# AVR32SD28 device description
Architecture: AVR8X; Family: AVR
Registers are 8-bit, read-write, reset 0x0 unless marked. A register's access mark holds for its fields unless they carry their own. Offsets are from the block's base; [hi:lo] are bit positions; {n}, {i} and the like mark numbered series; <NAME> marks a mode.

## AC — Analog Comparator
Instances: AC0 0x0680, AC1 0x0688, AC2 0x0690
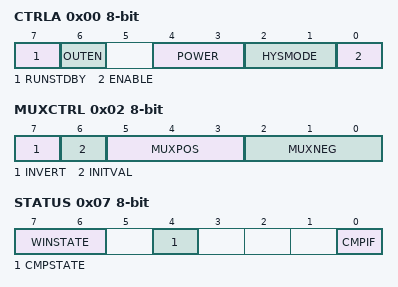
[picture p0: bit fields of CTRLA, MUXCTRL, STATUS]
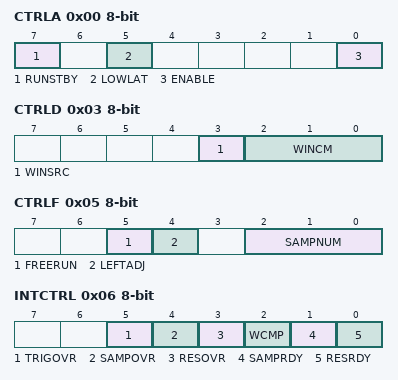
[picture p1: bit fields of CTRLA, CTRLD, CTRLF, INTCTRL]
0x00 CTRLA — Control A
  [7] RUNSTDBY — Run in Standby Mode
  [6] OUTEN — Output Pad Enable
  [4:3] POWER — Power profile
    0=PROFILE0 (Power profile 0, Shortest response time, highest consumption); 1=PROFILE1 (Power profile 1); 2=PROFILE2 (Power profile 2)
  [2:1] HYSMODE — Hysteresis Mode
    0=NONE (No hysteresis); 1=SMALL (Small hysteresis); 2=MEDIUM (Medium hysteresis); 3=LARGE (Large hysteresis)
  [0] ENABLE
0x01 CTRLB — Control B
  [1:0] WINSEL — Window selection mode
    0=DISABLED (Window function disabled); 1=UPSEL1 (Select ACn+1 as upper limit in window compare); 2=UPSEL2 (Select ACn+2 as upper limit in window compare)
0x02 MUXCTRL — Mux Control A
  [7] INVERT — Invert AC Output
  [6] INITVAL — AC Output Initial Value
    0=LOW (Output initialized to 0); 1=HIGH (Output initialized to 1)
  [5:3] MUXPOS — Positive Input MUX Selection
    {v}=AINP{v} (Positive Pin {v}) (v=0..4)
  [2:0] MUXNEG — Negative Input MUX Selection
    0=AINN0 (Negative Pin 0); 2=AINN2 (Negative Pin 2); 3=AINN3 (Negative Pin 3); 4=DACREF (DAC Reference)
0x05 DACREF reset 0xFF — DAC Voltage Reference
0x06 INTCTRL (modes: NORMAL when AC.CTRLB.WINSEL=0x0; WINDOW when AC.CTRLB.WINSEL=0x1 0x2) — Interrupt Control
  [0] CMP — Interrupt Enable
  [5:4] INTMODE <NORMAL> — Interrupt Mode
    0=BOTHEDGE (Positive and negative inputs crosses); 2=NEGEDGE (Positive input goes below negative input); 3=POSEDGE (Positive input goes above negative input)
  [5:4] INTMODE <WINDOW> — Interrupt Mode
    0=ABOVE (Window interrupt when input above both references); 1=INSIDE (Window interrupt when input betweeen references); 2=BELOW (Window interrupt when input below both references); 3=OUTSIDE (Window interrupt when input outside reference)
0x07 STATUS
  [7:6] WINSTATE ro — Analog Comparator Window State
    0=ABOVE (Above window); 1=INSIDE (Inside window); 2=BELOW (Below window)
  [4] CMPSTATE ro — Analog Comparator State
  [0] CMPIF — Analog Comparator Interrupt Flag

## ADC — Analog to Digital Converter
Instances: ADC0 0x0600, ADC1 0x0640
0x00 CTRLA — Control A
  [7] RUNSTBY — Run standby mode
  [5] LOWLAT — Conversion mode
  [0] ENABLE — ADC Enable
0x01 CTRLB — Control C
  [3:0] PRESC — Clock Pre-scaler
    0=DIV2 (CLK_PER divided by 2); 1=DIV4 (CLK_PER divided by 4); 2=DIV6 (CLK_PER divided by 6); 3=DIV8 (CLK_PER divided by 8); 4=DIV10 (CLK_PER divided by 10); 5=DIV12 (CLK_PER divided by 12); 6=DIV14 (CLK_PER divided by 14); 7=DIV16 (CLK_PER divided by 16); 8=DIV20 (CLK_PER divided by 20); 9=DIV24 (CLK_PER divided by 24); 10=DIV28 (CLK_PER divided by 28); 11=DIV32 (CLK_PER divided by 32); 12=DIV40 (CLK_PER divided by 40); 13=DIV48 (CLK_PER divided by 48); 14=DIV56 (CLK_PER divided by 56); 15=DIV64 (CLK_PER divided by 64)
0x02 CTRLC — Control B
  [2:0] REFSEL — Reference Selection
    0=VDD; 2=EXTVREF (VREFA for ADC0, VREFB for ADC1); 4=1V024 (1.024V); 5=2V048 (2.048V); 6=4V096 (4.096V); 7=2V500 (2.5V)
0x03 CTRLD — Control E
  [3] WINSRC — Window Mode Source
  [2:0] WINCM — Window Comparator Mode
    0=NONE (No Window Comparison); 1=BELOW (Below Window); 2=ABOVE (Above Window); 3=INSIDE (Inside Window); 4=OUTSIDE (Outside Window)
0x04 CTRLE — Control F
  [7:0] SAMPDUR — Sample Duration
0x05 CTRLF — Control D
  [5] FREERUN — Free Running
  [4] LEFTADJ — Left Adjust
  [2:0] SAMPNUM — Sampling Number
    0=NONE (No accumulation); 1=ACC2 (2 results accumulated); 2=ACC4 (4 results accumulated); 3=ACC8 (8 results accumulated); 4=ACC16 (16 results accumulated); 5=ACC32 (32 results accumulated); 6=ACC64 (64 results accumulated)
0x06 INTCTRL — Interrupt Control
  [5] TRIGOVR — Trigger Overrun Interrupt Enable
  [4] SAMPOVR — Sample Overwrite Interrupt Enable
  [3] RESOVR — Result Overwrite Interrupt Enable
  [2] WCMP — Window Comparator Interrupt Enable
  [1] SAMPRDY — Sample Ready Interrupt Enable
  [0] RESRDY — Result Ready Interrupt Enable
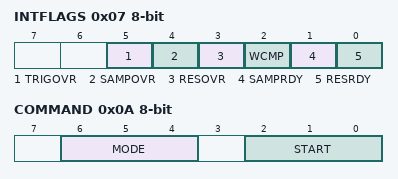
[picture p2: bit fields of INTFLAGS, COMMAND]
0x07 INTFLAGS — Interrupt Flags
  [5] TRIGOVR — Trigger OverrunFlag
  [4] SAMPOVR — Sample OverwriteFlag
  [3] RESOVR — Result OverwriteFlag
  [2] WCMP — Window Comparator Flag
  [1] SAMPRDY — Sample Ready Flag
  [0] RESRDY — Result Ready Flag
0x08 STATUS ro
  [0] ADCBUSY
0x09 DBGCTRL — Debug Control
  [0] DBGRUN — Debug run
0x0A COMMAND
  [6:4] MODE
    0=SINGLE_8BIT (Single 8-bit conv); 1=SINGLE_10BIT (Single 10-bit conv); 2=SERIES (Series of 10-bit conv); 3=BURST (Burst of 10-bit conv); 7=ACCTEST (Acc test mode for FuSa)
  [2:0] START — Start Conversion
    0=STOP (Stop/No ongoing conv); 1=IMMEDIATE (Start Immediately); 2=MUXPOS_WRITE (Start after a write to MUXPOS); 4=EVENT_TRIGGER (Start upon event reception)
0x0B MUXPOS — Positive mux input
  [6:0] MUXPOS — Analog Channel Selection Bits
    {v}=AIN{v} (ADC input pin {v}) (v=0..11); {v}=AIN{v} (ADC input pin {v}) (v=16..31); 64=GND (Ground); 65=VDDCOREDIV4 (VDDCORE/4); 66=TEMPSENSE (Temperature sensor); 68=VDDDIV10 (VDD/10); 69=VDDIO2DIV10 (VDDIO2/10); 72=DAC0; 73=DACREF0; 74=DACREF1; 75=DACREF2
0x0C RESULT 16-bit ro reset not defined — ADC Accumulator Result
  [15:0] RESULT — ADC Result
0x0E SAMPLE 16-bit — ADC Sample
  [15:0] SAMPLE ro
0x10 WINLT 16-bit reset not defined — Window comparator low threshold
  [15:0] WINLT — Window Low Threshold
0x12 WINHT 16-bit reset not defined — Window comparator high threshold
  [15:0] WINHT — Window High Threshold
0x14 TEMP — Temporary Data
  [7:0] TEMP — Temporary
